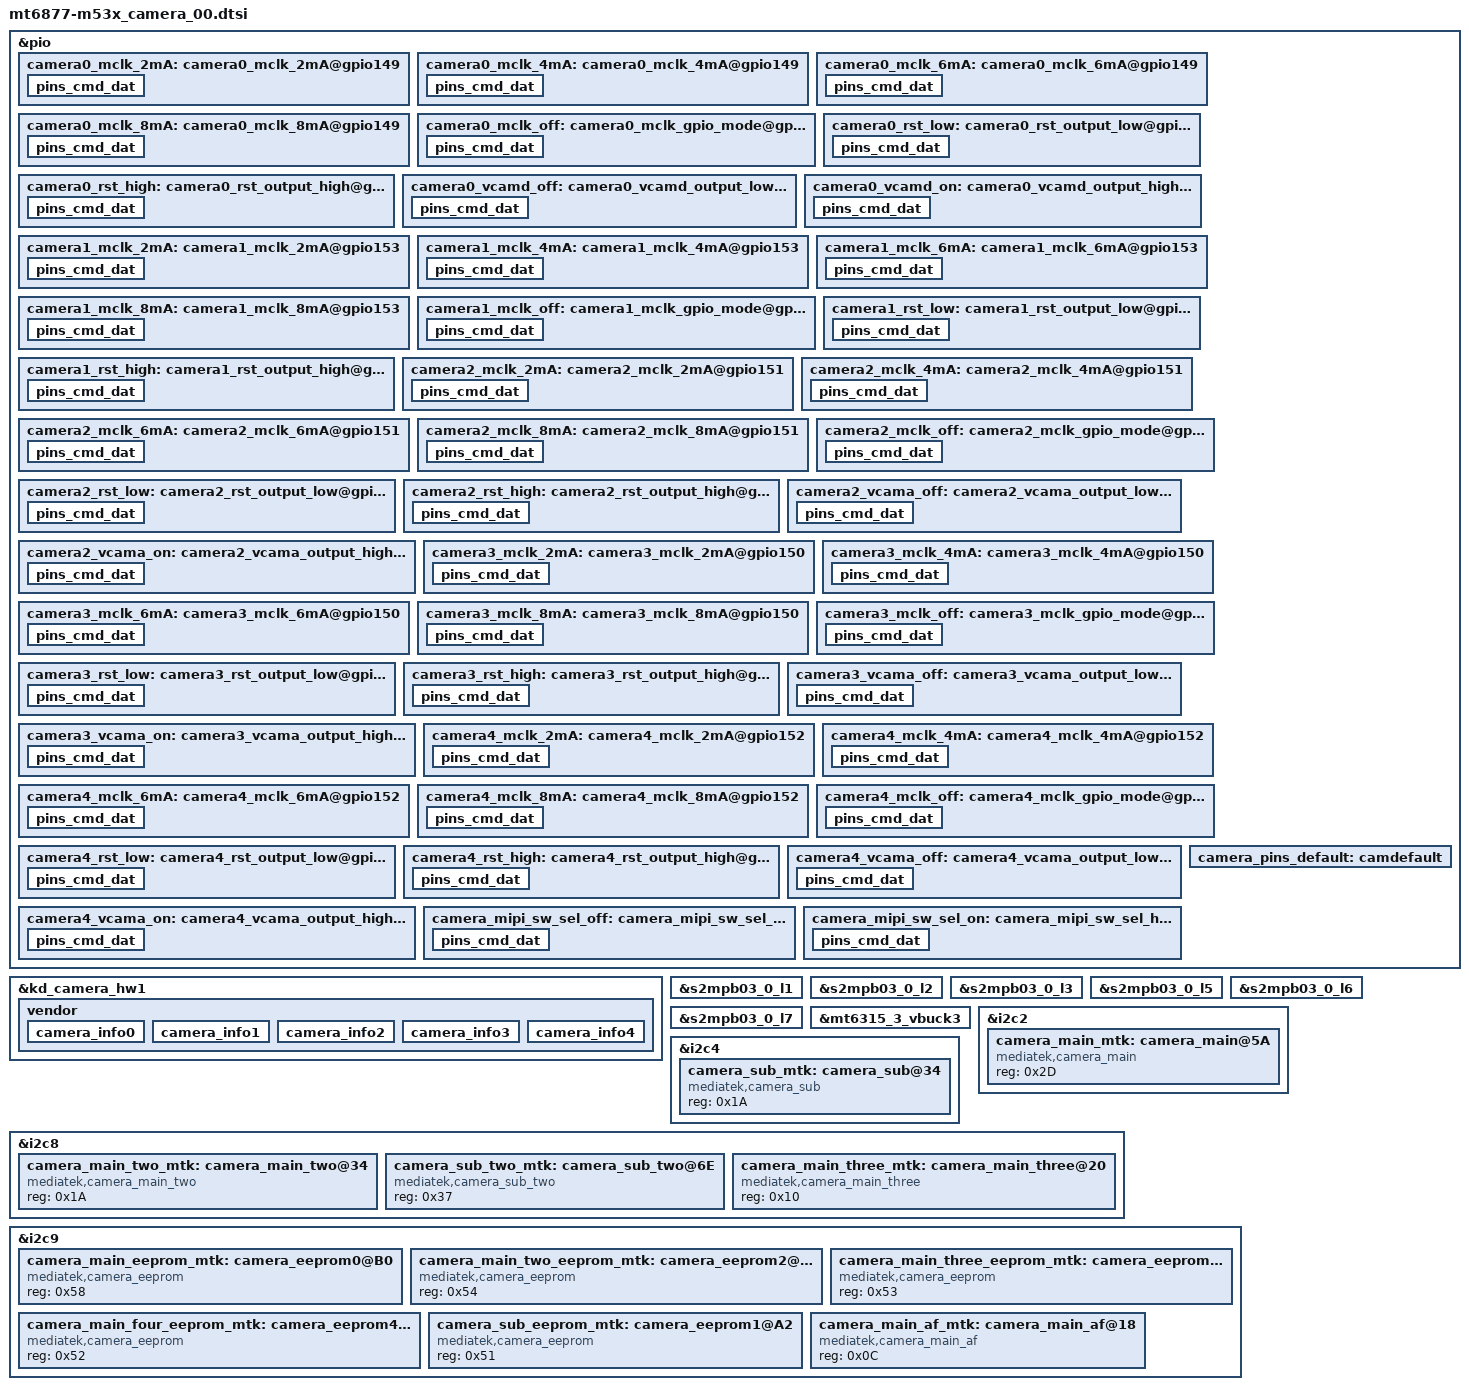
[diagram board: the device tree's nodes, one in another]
/*
 * Copyright (c) 2021 MediaTek Inc.
 *
 * This program is free software; you can redistribute it and/or modify
 * it under the terms of the GNU General Public License version 2 as
 * published by the Free Software Foundation.
 *
 * This program is distributed in the hope that it will be useful,
 * but WITHOUT ANY WARRANTY; without even the implied warranty of
 * MERCHANTABILITY or FITNESS FOR A PARTICULAR PURPOSE.  See the
 * GNU General Public License for more details.
 */

/********  M53-5g Board  ***********
 *    SW          :   HW   : Sensor
 * camera0(Wide)  : RCAM1  : S5KHM6
 * camera1(Front) : FCAM   : IMX616
 * camera2(UW)    : RCAM3  : IMX355
 * camera3(Bokeh) : RCAM2  : GC02M1B
 * camera4(Macro) : RCAM4  : GC02M1
 ***********************************/

/* CAMERA GPIO standardization */
&pio {
	/****************  camera0  ***************/
	// MCLK
	camera0_mclk_2mA: camera0_mclk_2mA@gpio149 {
		pins_cmd_dat {
			pinmux = <PINMUX_GPIO149__FUNC_CMMCLK0>;
			drive-strength = <0>;
		};
	};
	camera0_mclk_4mA: camera0_mclk_4mA@gpio149 {
		pins_cmd_dat {
			pinmux = <PINMUX_GPIO149__FUNC_CMMCLK0>;
			drive-strength = <1>;
		};
	};
	camera0_mclk_6mA: camera0_mclk_6mA@gpio149 {
		pins_cmd_dat {
			pinmux = <PINMUX_GPIO149__FUNC_CMMCLK0>;
			drive-strength = <2>;
		};
	};
	camera0_mclk_8mA: camera0_mclk_8mA@gpio149 {
		pins_cmd_dat {
			pinmux = <PINMUX_GPIO149__FUNC_CMMCLK0>;
			drive-strength = <3>;
		};
	};
	camera0_mclk_off: camera0_mclk_gpio_mode@gpio149 {
		pins_cmd_dat {
			pinmux = <PINMUX_GPIO149__FUNC_GPIO149>;
			drive-strength = <3>;
		};
	};

	// Reset
	camera0_rst_low: camera0_rst_output_low@gpio155 {
		pins_cmd_dat {
			pinmux = <PINMUX_GPIO155__FUNC_GPIO155>;
			output-low;
		};
	};
	camera0_rst_high: camera0_rst_output_high@gpio155 {
		pins_cmd_dat {
			pinmux = <PINMUX_GPIO155__FUNC_GPIO155>;
			output-high;
		};
	};

	// DVDD
	camera0_vcamd_off: camera0_vcamd_output_low@gpio7 {
		pins_cmd_dat {
			pinmux = <PINMUX_GPIO7__FUNC_GPIO7>;
			slew-rate = <1>;
			output-low;
		};
	};
	camera0_vcamd_on: camera0_vcamd_output_high@gpio7 {
		pins_cmd_dat {
			pinmux = <PINMUX_GPIO7__FUNC_GPIO7>;
			slew-rate = <1>;
			output-high;
		};
	};

	// I2C
/*
	camera_main_i2c_scl_on: camera_main_i2c_scl_on@gpio143 {
		pins_cmd_dat {
			pinmux = <PINMUX_GPIO143__FUNC_SCL2>;
			bias-disable;
		};
	};
	camera_main_i2c_sda_on: camera_main_i2c_sda_on@gpio144 {
		pins_cmd_dat {
			pinmux = <PINMUX_GPIO144__FUNC_SDA2>;
			bias-disable;
		};
	};
	camera_main_i2c_scl_off: camera_main_i2c_scl_off@gpio143 {
		pins_cmd_dat {
			pinmux = <PINMUX_GPIO143__FUNC_GPIO143>;
			bias-disable;
		};
	};
	camera_main_i2c_sda_off: camera_main_i2c_sda_off@gpio144 {
		pins_cmd_dat {
			pinmux = <PINMUX_GPIO144__FUNC_GPIO144>;
			bias-disable;
		};
	};
*/
	// AVDD2_LDO_EN
/*
	camera0_vcama2_ldo_en_off: camera0_vcama2_ldo_en_output_low@gpio160 {
		pins_cmd_dat {
			pinmux = <PINMUX_GPIO160__FUNC_GPIO160>;
			output-low;
		};
	};
	camera0_vcama2_ldo_en_on: camera0_vcama2_ldo_en_output_high@gpio160 {
		pins_cmd_dat {
			pinmux = <PINMUX_GPIO160__FUNC_GPIO160>;
			output-high;
		};
	};
*/

	/****************  camera1  ***************/
	// MCLK
	camera1_mclk_2mA: camera1_mclk_2mA@gpio153 {
		pins_cmd_dat {
			pinmux = <PINMUX_GPIO153__FUNC_CMMCLK4>;
			drive-strength = <0>;
		};
	};
	camera1_mclk_4mA: camera1_mclk_4mA@gpio153 {
		pins_cmd_dat {
			pinmux = <PINMUX_GPIO153__FUNC_CMMCLK4>;
			drive-strength = <1>;
		};
	};
	camera1_mclk_6mA: camera1_mclk_6mA@gpio153 {
		pins_cmd_dat {
			pinmux = <PINMUX_GPIO153__FUNC_CMMCLK4>;
			drive-strength = <2>;
		};
	};
	camera1_mclk_8mA: camera1_mclk_8mA@gpio153 {
		pins_cmd_dat {
			pinmux = <PINMUX_GPIO153__FUNC_CMMCLK4>;
			drive-strength = <3>;
		};
	};
	camera1_mclk_off: camera1_mclk_gpio_mode@gpio153 {
		pins_cmd_dat {
			pinmux = <PINMUX_GPIO153__FUNC_GPIO153>;
			drive-strength = <2>;
		};
	};

	// Reset
	camera1_rst_low: camera1_rst_output_low@gpio154 {
		pins_cmd_dat {
			pinmux = <PINMUX_GPIO154__FUNC_GPIO154>;
			output-low;
		};
	};
	camera1_rst_high: camera1_rst_output_high@gpio154 {
		pins_cmd_dat {
			pinmux = <PINMUX_GPIO154__FUNC_GPIO154>;
			output-high;
		};
	};

	// I2C
/*
	camera_sub_i2c_scl_on: camera_sub_i2c_scl_on@gpio145 {
		pins_cmd_dat {
			pinmux = <PINMUX_GPIO145__FUNC_SCL4>;
			bias-pull-up;
		};
	};
	camera_sub_i2c_sda_on: camera_sub_i2c_sda_on@gpio146 {
		pins_cmd_dat {
			pinmux = <PINMUX_GPIO146__FUNC_SDA4>;
			bias-pull-up;
		};
	};
	camera_sub_i2c_scl_off: camera_sub_i2c_scl_off@gpio145 {
		pins_cmd_dat {
			pinmux = <PINMUX_GPIO145__FUNC_GPIO145>;
			bias-pull-down;
		};
	};
	camera_sub_i2c_sda_off: camera_sub_i2c_sda_off@gpio146 {
		pins_cmd_dat {
			pinmux = <PINMUX_GPIO146__FUNC_GPIO146>;
			bias-pull-down;
		};
	};
*/

	/****************  camera2  ***************/
	// MCLK
	camera2_mclk_2mA: camera2_mclk_2mA@gpio151 {
		pins_cmd_dat {
			pinmux = <PINMUX_GPIO151__FUNC_CMMCLK2>;
			drive-strength = <0>;
		};
	};
	camera2_mclk_4mA: camera2_mclk_4mA@gpio151 {
		pins_cmd_dat {
			pinmux = <PINMUX_GPIO151__FUNC_CMMCLK2>;
			drive-strength = <1>;
		};
	};
	camera2_mclk_6mA: camera2_mclk_6mA@gpio151 {
		pins_cmd_dat {
			pinmux = <PINMUX_GPIO151__FUNC_CMMCLK2>;
			drive-strength = <2>;
		};
	};
	camera2_mclk_8mA: camera2_mclk_8mA@gpio151 {
		pins_cmd_dat {
			pinmux = <PINMUX_GPIO151__FUNC_CMMCLK2>;
			drive-strength = <3>;
		};
	};
	camera2_mclk_off: camera2_mclk_gpio_mode@gpio151 {
		pins_cmd_dat {
			pinmux = <PINMUX_GPIO151__FUNC_GPIO151>;
			drive-strength = <2>;
		};
	};

	// Reset
	camera2_rst_low: camera2_rst_output_low@gpio161 {
		pins_cmd_dat {
			pinmux = <PINMUX_GPIO161__FUNC_GPIO161>;
			output-low;
		};
	};
	camera2_rst_high: camera2_rst_output_high@gpio161 {
		pins_cmd_dat {
			pinmux = <PINMUX_GPIO161__FUNC_GPIO161>;
			output-high;
		};
	};

	// AVDD
	camera2_vcama_off: camera2_vcama_output_low@gpio20 {
		pins_cmd_dat {
			pinmux = <PINMUX_GPIO20__FUNC_GPIO20>;
			slew-rate = <1>;
			output-low;
		};
	};
	camera2_vcama_on: camera2_vcama_output_high@gpio20 {
		pins_cmd_dat {
			pinmux = <PINMUX_GPIO20__FUNC_GPIO20>;
			slew-rate = <1>;
			output-high;
		};
	};

	// I2C
/*
	camera_main_two_i2c_scl_on: camera_main_two_i2c_scl_on@gpio136 {
		pins_cmd_dat {
			pinmux = <PINMUX_GPIO136__FUNC_SCL8>;
			bias-pull-up;
		};
	};
	camera_main_two_i2c_sda_on: camera_main_two_i2c_sda_on@gpio137 {
		pins_cmd_dat {
			pinmux = <PINMUX_GPIO137__FUNC_SDA8>;
			bias-pull-up;
		};
	};
	camera_main_two_i2c_scl_off: camera_main_two_i2c_scl_off@gpio136 {
		pins_cmd_dat {
			pinmux = <PINMUX_GPIO136__FUNC_GPIO136>;
			bias-pull-down;
		};
	};
	camera_main_two_i2c_sda_off: camera_main_two_i2c_sda_off@gpio137 {
		pins_cmd_dat {
			pinmux = <PINMUX_GPIO137__FUNC_GPIO137>;
			bias-pull-down;
		};
	};
*/

	/****************  camera3  ***************/
	// MCLK
	camera3_mclk_2mA: camera3_mclk_2mA@gpio150 {
		pins_cmd_dat {
			pinmux = <PINMUX_GPIO150__FUNC_CMMCLK1>;
			drive-strength = <0>;
		};
	};
	camera3_mclk_4mA: camera3_mclk_4mA@gpio150 {
		pins_cmd_dat {
			pinmux = <PINMUX_GPIO150__FUNC_CMMCLK1>;
			drive-strength = <1>;
		};
	};
	camera3_mclk_6mA: camera3_mclk_6mA@gpio150 {
		pins_cmd_dat {
			pinmux = <PINMUX_GPIO150__FUNC_CMMCLK1>;
			drive-strength = <2>;
		};
	};
	camera3_mclk_8mA: camera3_mclk_8mA@gpio150 {
		pins_cmd_dat {
			pinmux = <PINMUX_GPIO150__FUNC_CMMCLK1>;
			drive-strength = <3>;
		};
	};
	camera3_mclk_off: camera3_mclk_gpio_mode@gpio150 {
		pins_cmd_dat {
			pinmux = <PINMUX_GPIO150__FUNC_GPIO150>;
			drive-strength = <2>;
		};
	};

	// Reset
	camera3_rst_low: camera3_rst_output_low@gpio159 {
		pins_cmd_dat {
			pinmux = <PINMUX_GPIO159__FUNC_GPIO159>;
			output-low;
		};
	};
	camera3_rst_high: camera3_rst_output_high@gpio159 {
		pins_cmd_dat {
			pinmux = <PINMUX_GPIO159__FUNC_GPIO159>;
			output-high;
		};
	};

	// AVDD & DVDD
	camera3_vcama_off: camera3_vcama_output_low@gpio10 {
		pins_cmd_dat {
			pinmux = <PINMUX_GPIO10__FUNC_GPIO10>;
			slew-rate = <1>;
			output-low;
		};
	};
	camera3_vcama_on: camera3_vcama_output_high@gpio10 {
		pins_cmd_dat {
			pinmux = <PINMUX_GPIO10__FUNC_GPIO10>;
			slew-rate = <1>;
			output-high;
		};
	};

	// I2C
/*
	camera_main_three_i2c_scl_on: camera_main_three_i2c_scl_on@gpio136 {
		pins_cmd_dat {
			pinmux = <PINMUX_GPIO136__FUNC_SCL8>;
			bias-pull-up;
		};
	};
	camera_main_three_i2c_sda_on: camera_main_three_i2c_sda_on@gpio137 {
		pins_cmd_dat {
			pinmux = <PINMUX_GPIO137__FUNC_SDA8>;
			bias-pull-up;
		};
	};
	camera_main_three_i2c_scl_off: camera_main_three_i2c_scl_off@gpio136 {
		pins_cmd_dat {
			pinmux = <PINMUX_GPIO136__FUNC_GPIO136>;
			bias-pull-down;
		};
	};
	camera_main_three_i2c_sda_off: camera_main_three_i2c_sda_off@gpio137 {
		pins_cmd_dat {
			pinmux = <PINMUX_GPIO137__FUNC_GPIO137>;
			bias-pull-down;
		};
	};
*/

	/****************  camera4  ***************/
	// MCLK
	camera4_mclk_2mA: camera4_mclk_2mA@gpio152 {
		pins_cmd_dat {
			pinmux = <PINMUX_GPIO152__FUNC_CMMCLK3>;
			drive-strength = <0>;
		};
	};
	camera4_mclk_4mA: camera4_mclk_4mA@gpio152 {
		pins_cmd_dat {
			pinmux = <PINMUX_GPIO152__FUNC_CMMCLK3>;
			drive-strength = <1>;
		};
	};
	camera4_mclk_6mA: camera4_mclk_6mA@gpio152 {
		pins_cmd_dat {
			pinmux = <PINMUX_GPIO152__FUNC_CMMCLK3>;
			drive-strength = <2>;
		};
	};
	camera4_mclk_8mA: camera4_mclk_8mA@gpio152 {
		pins_cmd_dat {
			pinmux = <PINMUX_GPIO152__FUNC_CMMCLK3>;
			drive-strength = <3>;
		};
	};
	camera4_mclk_off: camera4_mclk_gpio_mode@gpio152 {
		pins_cmd_dat {
			pinmux = <PINMUX_GPIO152__FUNC_GPIO152>;
			drive-strength = <2>;
		};
	};

	// Reset
	camera4_rst_low: camera4_rst_output_low@gpio163 {
		pins_cmd_dat {
			pinmux = <PINMUX_GPIO163__FUNC_GPIO163>;
			output-low;
		};
	};
	camera4_rst_high: camera4_rst_output_high@gpio163 {
		pins_cmd_dat {
			pinmux = <PINMUX_GPIO163__FUNC_GPIO163>;
			output-high;
		};
	};

	// AVDD & DVDD
	camera4_vcama_off: camera4_vcama_output_low@gpio10 {
		pins_cmd_dat {
			pinmux = <PINMUX_GPIO10__FUNC_GPIO10>;
			slew-rate = <1>;
			output-low;
		};
	};
	camera4_vcama_on: camera4_vcama_output_high@gpio10 {
		pins_cmd_dat {
			pinmux = <PINMUX_GPIO10__FUNC_GPIO10>;
			slew-rate = <1>;
			output-high;
		};
	};

	// I2C
/*
	camera_main_four_i2c_scl_on: camera_main_four_i2c_scl_on@gpio136 {
		pins_cmd_dat {
			pinmux = <PINMUX_GPIO136__FUNC_SCL8>;
			bias-pull-up;
		};
	};
	camera_main_four_i2c_sda_on: camera_main_four_i2c_sda_on@gpio137 {
		pins_cmd_dat {
			pinmux = <PINMUX_GPIO137__FUNC_SDA8>;
			bias-pull-up;
		};
	};
	camera_main_four_i2c_scl_off: camera_main_four_i2c_scl_off@gpio136 {
		pins_cmd_dat {
			pinmux = <PINMUX_GPIO136__FUNC_GPIO136>;
			bias-pull-down;
		};
	};
	camera_main_four_i2c_sda_off: camera_main_four_i2c_sda_off@gpio137 {
		pins_cmd_dat {
			pinmux = <PINMUX_GPIO137__FUNC_GPIO137>;
			bias-pull-down;
		};
	};
*/
	// MIPI Switch
	camera_mipi_sw_sel_off: camera_mipi_sw_sel_low@gpio91 {
		pins_cmd_dat {
			pinmux = <PINMUX_GPIO91__FUNC_GPIO91>;
			output-low;
		};
	};
	camera_mipi_sw_sel_on: camera_mipi_sw_sel_high@gpio91 {
		pins_cmd_dat {
			pinmux = <PINMUX_GPIO91__FUNC_GPIO91>;
			output-high;
		};
	};

	/****************  default  ***************/
	camera_pins_default: camdefault {
	};
};
&kd_camera_hw1 {
	pinctrl-names = "default",
		"cam0_rst0", "cam0_rst1",
		"cam0_ldo_vcamd_0", "cam0_ldo_vcamd_1",
		"cam0_mclk_off",
		"cam0_mclk_2mA", "cam0_mclk_4mA",
		"cam0_mclk_6mA", "cam0_mclk_8mA",
		"cam1_rst0", "cam1_rst1",
		"cam1_mclk_off",
		"cam1_mclk_2mA", "cam1_mclk_4mA",
		"cam1_mclk_6mA", "cam1_mclk_8mA",
		"cam2_rst0", "cam2_rst1",
		"cam2_ldo_vcama_0", "cam2_ldo_vcama_1",
		"cam2_mclk_off",
		"cam2_mclk_2mA", "cam2_mclk_4mA",
		"cam2_mclk_6mA", "cam2_mclk_8mA",
		"cam3_rst0", "cam3_rst1",
		"cam3_ldo_vcama_0", "cam3_ldo_vcama_1",
		"cam3_mclk_off",
		"cam3_mclk_2mA", "cam3_mclk_4mA",
		"cam3_mclk_6mA", "cam3_mclk_8mA",
		"cam4_rst0", "cam4_rst1",
		"cam4_ldo_vcama_0", "cam4_ldo_vcama_1",
		"cam4_mclk_off",
		"cam4_mclk_2mA", "cam4_mclk_4mA",
		"cam4_mclk_6mA", "cam4_mclk_8mA",
		"cam_mipi_switch_sel_1", "cam_mipi_switch_sel_0";

	pinctrl-0 = <&camera_pins_default>;
	pinctrl-1 = <&camera0_rst_low>;
	pinctrl-2 = <&camera0_rst_high>;
	pinctrl-3 = <&camera0_vcamd_off>;
	pinctrl-4 = <&camera0_vcamd_on>;
	pinctrl-5 = <&camera0_mclk_off>;
	pinctrl-6 = <&camera0_mclk_2mA>;
	pinctrl-7 = <&camera0_mclk_4mA>;
	pinctrl-8 = <&camera0_mclk_6mA>;
	pinctrl-9 = <&camera0_mclk_8mA>;

	pinctrl-10 = <&camera1_rst_low>;
	pinctrl-11 = <&camera1_rst_high>;
	pinctrl-12 = <&camera1_mclk_off>;
	pinctrl-13 = <&camera1_mclk_2mA>;
	pinctrl-14 = <&camera1_mclk_4mA>;
	pinctrl-15 = <&camera1_mclk_6mA>;
	pinctrl-16 = <&camera1_mclk_8mA>;

	pinctrl-17 = <&camera2_rst_low>;
	pinctrl-18 = <&camera2_rst_high>;
	pinctrl-19 = <&camera2_vcama_off>;
	pinctrl-20 = <&camera2_vcama_on>;
	pinctrl-21 = <&camera2_mclk_off>;
	pinctrl-22 = <&camera2_mclk_2mA>;
	pinctrl-23 = <&camera2_mclk_4mA>;
	pinctrl-24 = <&camera2_mclk_6mA>;
	pinctrl-25 = <&camera2_mclk_8mA>;

	pinctrl-26 = <&camera3_rst_low>;
	pinctrl-27 = <&camera3_rst_high>;
	pinctrl-28 = <&camera3_vcama_off>;
	pinctrl-29 = <&camera3_vcama_on>;
	pinctrl-30 = <&camera3_mclk_off>;
	pinctrl-31 = <&camera3_mclk_2mA>;
	pinctrl-32 = <&camera3_mclk_4mA>;
	pinctrl-33 = <&camera3_mclk_6mA>;
	pinctrl-34 = <&camera3_mclk_8mA>;

	pinctrl-35 = <&camera4_rst_low>;
	pinctrl-36 = <&camera4_rst_high>;
	pinctrl-37 = <&camera4_vcama_off>;
	pinctrl-38 = <&camera4_vcama_on>;
	pinctrl-39 = <&camera4_mclk_off>;
	pinctrl-40 = <&camera4_mclk_2mA>;
	pinctrl-41 = <&camera4_mclk_4mA>;
	pinctrl-42 = <&camera4_mclk_6mA>;
	pinctrl-43 = <&camera4_mclk_8mA>;

	pinctrl-44 = <&camera_mipi_sw_sel_on>;
	pinctrl-45 = <&camera_mipi_sw_sel_off>;

	/********* Regulator setting **************/
	// camera0
	cam0_vcama-supply = <&s2mpb03_0_l5>;
	cam0_vcamd2-supply = <&mt6315_3_vbuck3>;
	cam0_vcamio-supply = <&s2mpb03_0_l3>;
	cam0_vcamaf-supply = <&s2mpb03_0_l7>;

	// camera1
	cam1_vcama-supply = <&s2mpb03_0_l6>;
	cam1_vcamd-supply = <&s2mpb03_0_l1>;
	cam1_vcamio-supply = <&s2mpb03_0_l3>;

	// camera2
	cam2_vcamd-supply = <&s2mpb03_0_l2>;
	cam2_vcamio-supply = <&s2mpb03_0_l3>;

	// camera3
	cam3_vcamio-supply = <&s2mpb03_0_l3>;

	// camera4
	cam4_vcamio-supply = <&s2mpb03_0_l3>;

	status = "okay";
	vendor {
		rear_sensor_id = <120>;     /* SENSOR_NAME_S5KHM6 */
		front_sensor_id = <121>;    /* SENSOR_NAME_IMX616 */
		rear2_sensor_id = <210>;    /* SENSOR_NAME_IMX355 */
		rear3_sensor_id = <211>;    /* SENSOR_NAME_GC02M1B */
		rear4_sensor_id = <210>;    /* SENSOR_NAME_GC02M1 */

		use_dualcam_set_cal;
		//use_module_check;
		// skip_cal_loading;
		//check_final_cam_module;
		check_sensor_vendor;
		max_supported_camera = <5>;
		supported_cameraId = <0 1 50 52 54>;
		/* REAR, FRONT, UW, DUAL_REAR_PORTRAIT_WIDE(Bokeh), REAR_3(Macro) */

		max_camera_num = <5>;
		camera_info0 {             /* 0 : rear - S5KHM6 */
			isp = <0>;             /* 0 : INT , 1 : EXT , 2 : SOC */
			cal_memory = <0>;      /* 0 : N , 1 : FROM , 2 : EEPROM , 3 : OTP  */
			read_version = <0>;    /* 0 : SYSFS , 1 : CAMON */
			core_voltage = <0>;    /* 0 : N , 1 : Y  */
			upgrade = <0>;         /* 0 : N , 1 : SYSFS , 2 : CAMON */
			companion = <0>;       /* 0 : N , 1 : Y  */
			ois = <0>;             /* 0 : N , 1 : Y  */
			valid = <1>;           /* 0 : INVALID, 1 : VALID */
			dual_open = <0>;       /* 0 : SINGLE_OPEN , 1 : DUAL_OPEN */
			position = <0>;        /* 0 : Rear, 1:Front, 2:Rear2, 3:Front2, 4:Rear3, 6:Rear4 */
			//includes_sub = <4>;  /* include this for common eeprom. <_position_> - position of the sub camera */
			afcal_type=<20>;       /* output format - 1: Near, Middle..., Far , 20: Near, Far, Middle... */
			use_adaptive_mipi=<1>;  /* 0 : N, 1 : Y */
		};
		camera_info1 {             /* 1 : front - IMX616 */
			isp = <0>;             /* 0 : INT , 1 : EXT , 2 : SOC */
			cal_memory = <0>;      /* 0 : N , 1 : FROM , 2 : EEPROM , 3 : OTP  */
			read_version = <0>;    /* 0 : SYSFS , 1 : CAMON */
			core_voltage = <0>;    /* 0 : N , 1 : Y  */
			upgrade = <0>;         /* 0 : N , 1 : SYSFS , 2 : CAMON */
			companion = <0>;       /* 0 : N , 1 : Y  */
			ois = <0>;             /* 0 : N , 1 : Y  */
			valid = <1>;           /* 0 : INVALID, 1 : VALID */
			dual_open = <0>;       /* 0 : SINGLE_OPEN , 1 : DUAL_OPEN */
			position = <1>;        /* 0 : Rear, 1:Front, 2:Rear2, 3:Front2, 4:Rear3, 6:Rear4 */
			use_adaptive_mipi=<0>;  /* 0 : N, 1 : Y */
		};
		camera_info2 {             /* 3 : rear2 - IMX355 */
			isp = <0>;             /* 0 : INT , 1 : EXT , 2 : SOC */
			cal_memory = <0>;      /* 0 : N , 1 : FROM , 2 : EEPROM , 3 : OTP  */
			read_version = <0>;    /* 0 : SYSFS , 1 : CAMON */
			core_voltage = <0>;    /* 0 : N , 1 : Y  */
			upgrade = <0>;         /* 0 : N , 1 : SYSFS , 2 : CAMON */
			companion = <0>;       /* 0 : N , 1 : Y  */
			ois = <0>;             /* 0 : N , 1 : Y  */
			valid = <1>;           /* 0 : INVALID, 1 : VALID */
			dual_open = <0>;       /* 0 : SINGLE_OPEN , 1 : DUAL_OPEN */
			position = <2>;        /* 0 : Rear, 1:Front, 2:Rear2, 3:Front2, 4:Rear3, 6:Rear4 */
			use_adaptive_mipi=<1>;  /* 0 : N, 1 : Y */
		};
		camera_info3 {             /* 3 : rear3 - GC02M1B */
			isp = <0>;             /* 0 : INT , 1 : EXT , 2 : SOC */
			cal_memory = <0>;      /* 0 : N , 1 : FROM , 2 : EEPROM , 3 : OTP  */
			read_version = <0>;    /* 0 : SYSFS , 1 : CAMON */
			core_voltage = <0>;    /* 0 : N , 1 : Y  */
			upgrade = <0>;         /* 0 : N , 1 : SYSFS , 2 : CAMON */
			companion = <0>;       /* 0 : N , 1 : Y  */
			ois = <0>;             /* 0 : N , 1 : Y  */
			valid = <1>;           /* 0 : INVALID, 1 : VALID */
			dual_open = <0>;       /* 0 : SINGLE_OPEN , 1 : DUAL_OPEN */
			position = <4>;        /* 0 : Rear, 1:Front, 2:Rear2, 3:Front2, 4:Rear3, 6:Rear4 */
			use_adaptive_mipi=<0>;  /* 0 : N, 1 : Y */
		};
		camera_info4 {             /* 4 : rear4 - GC02M1 */
			isp = <0>;             /* 0 : INT , 1 : EXT , 2 : SOC */
			cal_memory = <0>;      /* 0 : N , 1 : FROM , 2 : EEPROM , 3 : OTP  */
			read_version = <0>;    /* 0 : SYSFS , 1 : CAMON */
			core_voltage = <0>;    /* 0 : N , 1 : Y  */
			upgrade = <0>;         /* 0 : N , 1 : SYSFS , 2 : CAMON */
			companion = <0>;       /* 0 : N , 1 : Y  */
			ois = <0>;             /* 0 : N , 1 : Y  */
			valid = <1>;           /* 0 : INVALID, 1 : VALID */
			dual_open = <0>;       /* 0 : SINGLE_OPEN , 1 : DUAL_OPEN */
			position = <6>;        /* 0 : Rear, 1:Front, 2:Rear2, 3:Front2, 4:Rear3, 6:Rear4 */
			use_adaptive_mipi=<0>;  /* 0 : N, 1 : Y */
		};
	};
};
/* CAMERA GPIO end */

/* CAM PMIC */
&s2mpb03_0_l1 {
	regulator-min-microvolt = <1050000>;
	regulator-max-microvolt = <1050000>;
};

&s2mpb03_0_l2 {
	regulator-min-microvolt = <1200000>;
	regulator-max-microvolt = <1200000>;
};

&s2mpb03_0_l3 {
	regulator-min-microvolt = <1800000>;
	regulator-max-microvolt = <1800000>;
};

&s2mpb03_0_l5 {
	regulator-min-microvolt = <2200000>;
	regulator-max-microvolt = <2200000>;
};

&s2mpb03_0_l6 {
	regulator-min-microvolt = <2900000>;
	regulator-max-microvolt = <2900000>;
};

&s2mpb03_0_l7 {
	regulator-min-microvolt = <2800000>;
	regulator-max-microvolt = <2800000>;
};

&mt6315_3_vbuck3 {
	regulator-min-microvolt = <1100000>;
	regulator-max-microvolt = <1193750>;
};
/*************************
*     Cmaera I2C
*************************/

&i2c2 {
	#address-cells = <1>;
	#size-cells = <0>;
	clock-frequency = <1000000>;
	mediatek,use-open-drain;
	camera_main_mtk:camera_main@5A {
		compatible = "mediatek,camera_main";
		reg = <0x2D>;
		status = "okay";
	};
};

&i2c4 {
	#address-cells = <1>;
	#size-cells = <0>;
	clock-frequency = <1000000>;
	mediatek,use-open-drain;
	camera_sub_mtk:camera_sub@34 {
		compatible = "mediatek,camera_sub";
		reg = <0x1A>;
		status = "okay";
	};
};

&i2c8 {
	#address-cells = <1>;
	#size-cells = <0>;
	clock-frequency = <400000>;
	mediatek,use-open-drain;

	camera_main_two_mtk:camera_main_two@34 {
		compatible = "mediatek,camera_main_two";
		reg = <0x1A>;
		status = "okay";
	};

	camera_sub_two_mtk:camera_sub_two@6E {
		compatible = "mediatek,camera_sub_two";
		reg = <0x37>;
		status = "okay";
	};

	camera_main_three_mtk:camera_main_three@20 {
		compatible = "mediatek,camera_main_three";
		reg = <0x10>;
		status = "okay";
	};
};

&i2c9 {
	#address-cells = <1>;
	#size-cells = <0>;
	clock-frequency = <400000>;
	mediatek,use-open-drain;

	/* Rear camera */
	camera_main_eeprom_mtk:camera_eeprom0@B0 {
		compatible = "mediatek,camera_eeprom";
		reg = <0x58>;
		status = "okay";
	};

	camera_main_two_eeprom_mtk:camera_eeprom2@A8 {
		compatible = "mediatek,camera_eeprom";
		reg = <0x54>;
		status = "okay";
	};

	camera_main_three_eeprom_mtk:camera_eeprom3@A6 {
		compatible = "mediatek,camera_eeprom";
		reg = <0x53>;
		status = "okay";
	};

	camera_main_four_eeprom_mtk:camera_eeprom4@A4 {
		compatible = "mediatek,camera_eeprom";
		reg = <0x52>;
		status = "okay";
	};

	camera_sub_eeprom_mtk:camera_eeprom1@A2 {
		compatible = "mediatek,camera_eeprom";
		reg = <0x51>;
		status = "okay";
	};

	camera_main_af_mtk:camera_main_af@18 {
		compatible = "mediatek,camera_main_af";
		reg = <0x0C>;
		status = "okay";
	};
};
